# IND83212 register map
Series: Verne; File version: B0
CPU: CM0 r0p1, selectable endian, no MPU, no FPU, 4 interrupt priority bits
Registers are 32-bit, read-write, no defined reset value unless marked. A register's access mark holds for its fields unless they carry their own. Offsets are from the block's base; [hi:lo] are bit positions; {n}, {i} and the like mark numbered series.

## WDTA — Watchdog Timer Registers
Base 0x50010300; register names take the prefix WDTA_
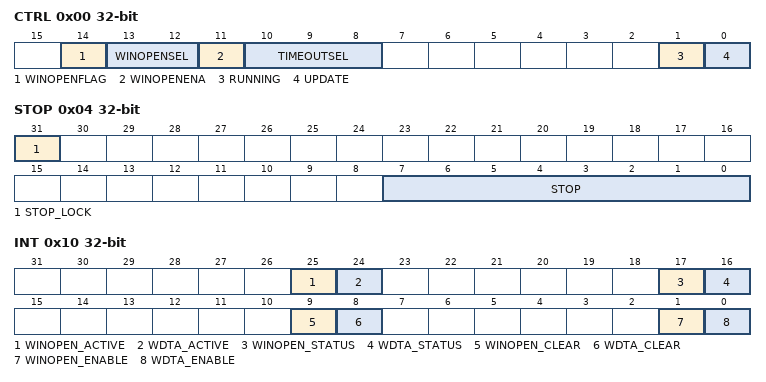
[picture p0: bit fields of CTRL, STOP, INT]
0x00 CTRL — Control
  [14] WINOPENFLAG ro — Window open flag. A flag that indicates when the watchdog window is open. It only can be cleared by Reg CLEAR! 0x0: Window is Closed 0x1: Window is Open
  [13:12] WINOPENSEL — Window Mode open select. Defines the watchdog window open time (the time between the watchdog start and the window open). 0x0: 1/2 * WDT timeout 0x1: 1/4 * WDT timeout 0x2: 1/8 * WDT timeout 0x3: 1/16* WDT timeout
  [11] WINOPENENA — Window Mode Enable. Enables Window Mode. 1'b1: Enable the Window mode of Watchdog, if the WDT is cleared before the time window opens, the WDT will issue a system reset. 1'b0: Disable the Window mode of Watchdog.
  [10:8] TIMEOUTSEL — Timeout select. Defines the watchdog timeout period (the time between a clear operation and the next timeout). 0x0: 2^10 * 62.5us ~= 128 ms 0x1: 2^11 * 62.5us ~= 256 ms 0x2: 2^12 * 62.5us ~= 512 ms 0x3: 2^13 * 62.5us ~= 1.0 s 0x4: 2^14 * 62.5us ~= 2.0 s 0x5: 2^15 * 62.5us ~= 4.0 s 0x6: 2^16 * 62.5us ~= 8.0 s 0x7: 2^17 * 62.5us ~= 16.0 s
  [1] RUNNING ro — Running status. A flag that indicates when the watchdog timer is enabled. 0x0: Watchdog timer is stopped and cleared 0x1: Watchdog timer is running
  [0] UPDATE dual — Window Mode Enable. Set to update Analog-Watchdog Configurations. NOTE: DO NOT change the CTRL register when it is high, which indicates there is an update in progress, It gets cleared by the core when the current update is done
0x04 STOP
  [31] STOP_LOCK — Set Only bit. Set this bit to lock STOP bits.
  [7:0] STOP — Stop. Write the *stop* code (0xc3) to this register to reset the timer and disable the watchdog (e.g. during debug). If any other value is written to this register the watchdog will be enabled.
0x08 CLEAR
  [31:0] CLEAR wo — Clear. Write the value 0x3c574ad6 (as a single word access) to reset the watchdog timer. Periodically performing this action is the expected method of preventing the watchdog from timing out (and resetting the MCU).
0x0C CNTVAL — Counter value
  [31:0] CLEAR ro — Counter value. The instantaneous value of watchdog timeout counter
0x10 INT — WDTA Interrupts
  [25] WINOPEN_ACTIVE ro — Window Open Interrupt. Set by WDTA timeout
  [24] WDTA_ACTIVE ro — WDTA timeout Interrupt. Set by WDTA timeout
  [17] WINOPEN_STATUS ro — Window Open Status. Set by WDTA timeout
  [16] WDTA_STATUS ro — WDTA timeout Status. Set by WDTA timeout
  [9] WINOPEN_CLEAR wo — Window Open Interrupt Clear. Autoclear: includes a synchronous reset signal which clears the register on the cycle following write.
  [8] WDTA_CLEAR wo — WDTA timeout Interrupt Clear. Autoclear: includes a synchronous reset signal which clears the register on the cycle following write.
  [1] WINOPEN_ENABLE — Window Open Interrupt Enable.
  [0] WDTA_ENABLE — WDTA timeout Interrupt Enable.

## PWM — Control (and status) registers for the pulse width modulation waveform generator.
Base 0x50010600; register names take the prefix PWM_
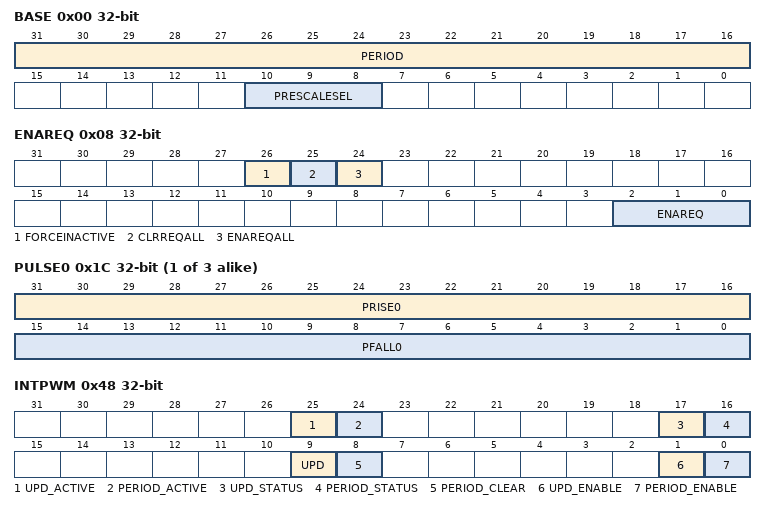
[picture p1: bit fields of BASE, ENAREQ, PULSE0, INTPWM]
0x00 BASE — Base functions
  [31:16] PERIOD — Period. Specifies the period of the output waveform in terms of a number of prescaler output cycles.
  [10:8] PRESCALESEL — Prescaler select. Defines the ratio between the system clock and the clock used for the waveform generator. 0x0: Divide by 1 0x1: Divide by 2 0x2: Divide by 4 0x3: Divide by 8 0x4: Divide by 16 0x5: Divide by 64 0x6: Divide by 256 0x7: Divide by 1024
0x04 PWMCNT — PWM Count Value
  [15:0] PWMCNT dual — PWM counter value to give a sense about the current period
0x08 ENAREQ — Enable request
  [26] FORCEINACTIVE — Set to force PWM signals return to initial value immediately.
  [25] CLRREQALL wo — Write 1 to clear all ENA_REQ bits; Write 0 has no effects.
  [24] ENAREQALL wo — Write 1 to enable all ENA_REQ bits; Write 0 has no effects.
  [2:0] ENAREQ — Set to enable the waveform generator.
0x0C ENASTS — Enable status
  [2:0] ENASTS ro — Status of enable in the waveform generator.
0x10 INIT — Intial State of Outputs
  [2:0] INIT — Set to initialise the output waveform.
0x14 INV — Invert
  [2:0] INVERT — Set to initialise the output waveform.
0x18 UPDATE
  [0] UPDATE dual — Set to trigger consumption of new PULSE parameters (invert,prescale_sel,period,pulse start & stop). The flag is automatically cleared by the hardware when the settings are consumed, so reading a high value indicates that an update is still pending.
{0x1C+4i} PULSE{i} (i=0..2) — PWM{i} pulse setup
  [31:16] PRISE{i} — Pulse Rise. Specifies the pulse rise of the output waveform in terms of a number of prescaler output cycles. However, if INVERT is set it determines the pulse fall timing.
  [15:0] PFALL{i} — Pulse Fall. Specifies the pulse fall of the output waveform in terms of a number of prescaler output cycles. However, if INVERT is set it determines the pulse rise timing.
0x28 INTPOSEDGENA — PWM posedge interrupt enable
  [2:0] INTPOSEDGENA — Interrupt enable. bit[2:0]: posedge interrupt enable.
0x2C INTNEGEDGENA — PWM negedge interrupt enable
  [2:0] INTNEGEDGENA — Interrupt enable. bit[2:0]: negedge interrupt enable.
0x30 INTPOSEDGCLR — PWM posedge interrupt control
  [2:0] INTPOSEDGCLR wo — Interrupt clear. bit[2:0] : posedge interrupt clear.
0x34 INTNEGEDGCLR — PWM negedge interrupt control
  [2:0] INTNEGEDGCLR wo — Interrupt clear. bit[2:0] : negedge interrupt clear.
0x38 INTPOSEDGSTS — PWM posedge interrupt status
  [2:0] INTPOSEDGSTS ro — Interrupt status. bit[2:0] : posedge interrupt status.
0x3C INTNEGEDGSTS — PWM negedge interrupt status
  [2:0] INTNEGEDGSTS ro — Interrupt status. bit[2:0] : negedge interrupt status.
0x40 INTPOSEDGIRQ — PWM posedge interrupt active
  [2:0] INTPOSEDGIRQ ro — Interrupt active. bit[2:0] : posedge interrupt active.
0x44 INTNEGEDGIRQ — PWM negedge interrupt active
  [2:0] INTNEGEDGIRQ ro — Interrupt active. bit[2:0] : negedge interrupt active.
0x48 INTPWM — PWM interrupt control
  [25] UPD_ACTIVE ro — Updated Interrupt active.
  [24] PERIOD_ACTIVE ro — Period Interrupt active.
  [17] UPD_STATUS ro — Updated Interrupt status.
  [16] PERIOD_STATUS ro — Period Interrupt status.
  [9] UPD wo — Updated Interrupt clear.
  [8] PERIOD_CLEAR wo — Period Interrupt clear.
  [1] UPD_ENABLE — Updated Interrupt enable.
  [0] PERIOD_ENABLE — Period Interrupt enable.
